# GD32F527 register map
File version: 1.0
CPU: CM33 r0p1, little endian, MPU, FPU, 4 interrupt priority bits
Registers are 32-bit, read-write, reset 0x0 unless marked. A register's access mark holds for its fields unless they carry their own. Offsets are from the block's base; [hi:lo] are bit positions; lines under a group give offsets from that group; {n}, {i} and the like mark numbered series.

## ADC0 — Analog to digital converter
Base 0x40012000
Same registers: ADC1 0x40012100, ADC2 0x40012200
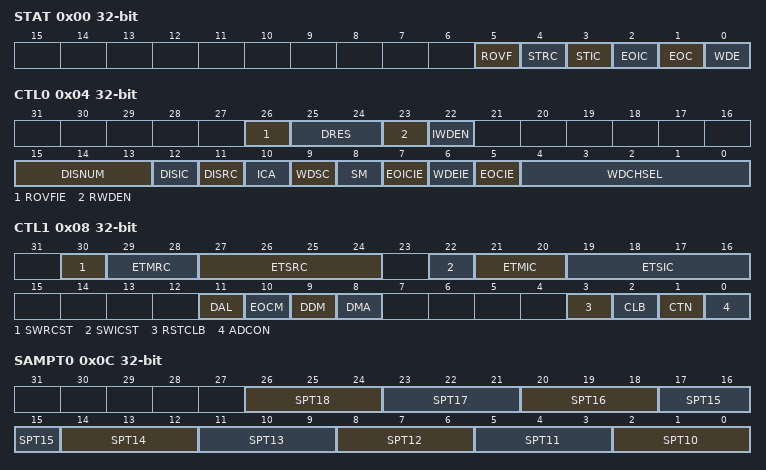
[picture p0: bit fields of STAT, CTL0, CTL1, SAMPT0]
0x00 STAT — status register
  [5] ROVF — Regular data register overflow
  [4] STRC — Start flag of regular channel group
  [3] STIC — Start flag of inserted channel group
  [2] EOIC — End of inserted group conversion flag
  [1] EOC — End of group conversion flag
  [0] WDE — Analog watchdog event flag
0x04 CTL0 — control register 0
  [26] ROVFIE — Interrupt enable for ROVF
  [25:24] DRES — ADC data resolution
  [23] RWDEN — Regular channel analog watchdog enable
  [22] IWDEN — Inserted channel analog watchdog enable
  [15:13] DISNUM — Number of conversions in discontinuous mode
  [12] DISIC — Discontinuous mode on inserted channels
  [11] DISRC — Discontinuous mode on regular channels
  [10] ICA — Inserted channel group convert automatically
  [9] WDSC — When in scan mode, analog watchdog is effective on a single channel
  [8] SM — Scan mode
  [7] EOICIE — Interrupt enable for EOIC
  [6] WDEIE — Analog watchdog WDE
  [5] EOCIE — Interrupt enable for EOC
  [4:0] WDCHSEL — Analog watchdog channel select
0x08 CTL1 — control register 1
  [30] SWRCST — Software start on regular channel
  [29:28] ETMRC — External trigger mode for regular channel
  [27:24] ETSRC — External trigger select for regular channel
  [22] SWICST — Software start on inserted channel
  [21:20] ETMIC — External trigger mode for inserted channel
  [19:16] ETSIC — External trigger select for inserted channel
  [11] DAL — Data alignment
  [10] EOCM — End of conversion mode
  [9] DDM — DMA disable mode
  [8] DMA — DMA request enable
  [3] RSTCLB — Reset calibration
  [2] CLB — ADC calibration
  [1] CTN — Continuous mode
  [0] ADCON
0x0C SAMPT0 — Sample time register 0
  [3n-28:3n-30] SPT{n} (n=10..18) — Channel {n} sample time selection
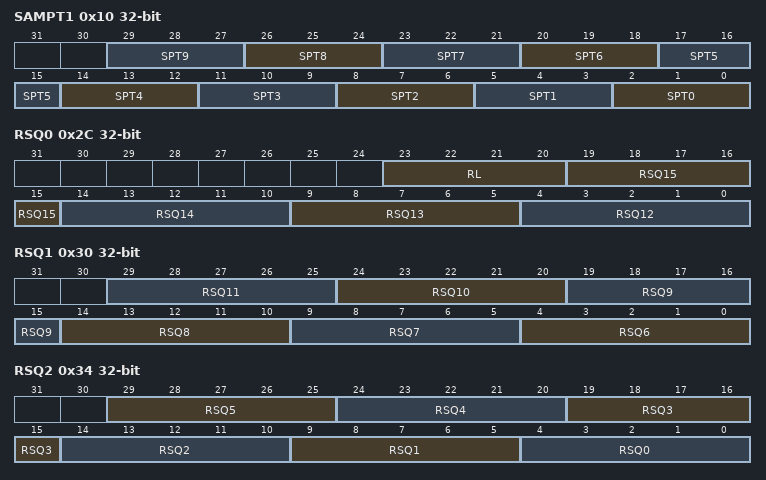
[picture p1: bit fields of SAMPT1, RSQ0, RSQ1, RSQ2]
0x10 SAMPT1 — Sample time register 1
  [3n+2:3n] SPT{n} (n=0..9) — Channel {n} sample time selection
{0x14+4i} IOFF{i} (i=0..3) — Inserted channel data offset register {i}
  [11:0] IOFF — Data offset for inserted channel {i}
0x24 WDHT reset 0xFFF — watchdog higher threshold register
  [11:0] WDHT — Analog watchdog higher threshold
0x28 WDLT — watchdog lower threshold register
  [11:0] WDLT — Analog watchdog lower threshold
0x2C RSQ0 — regular sequence register 0
  [23:20] RL — Regular channel group length
  [5n-56:5n-60] RSQ{n} (n=12..15) — {n+1}th conversion in regular sequence
0x30 RSQ1 — regular sequence register 1
  [5n-26:5n-30] RSQ{n} (n=6..11) — {n+1}th conversion in regular sequence
0x34 RSQ2 — regular sequence register 2
  [29:25] RSQ5 — 6th conversion in regular sequence
  [24:20] RSQ4 — 5th conversion in regular sequence
  [19:15] RSQ3 — 4th conversion in regular sequence
  [14:10] RSQ2 — 3rd conversion in regular sequence
  [9:5] RSQ1 — 2nd conversion in regular sequence
  [4:0] RSQ0 — 1st conversion in regular sequence
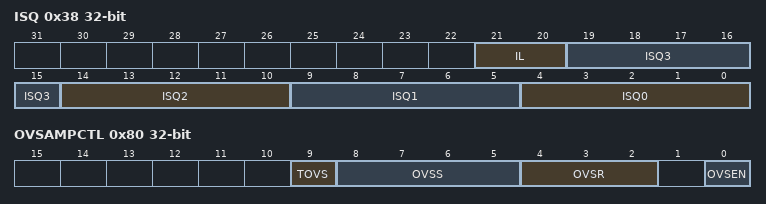
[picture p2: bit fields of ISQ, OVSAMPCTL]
0x38 ISQ — Inserted sequence register
  [21:20] IL — Inserted channel group length
  [19:15] ISQ3 — 4th conversion in inserted sequence
  [14:10] ISQ2 — 3rd conversion in inserted sequence
  [9:5] ISQ1 — 2nd conversion in inserted sequence
  [4:0] ISQ0 — 1st conversion in inserted sequence
{0x3C+4i} IDATA{i} ro (i=0..3) — Inserted data register {i}
  [15:0] IDATAn — Inserted number n conversion data
0x4C RDATA ro — regular data register
  [15:0] RDATA — Regular channel data
0x80 OVSAMPCTL ro — Oversample control register
  [9] TOVS — Triggered Oversampling
  [8:5] OVSS — Oversampling shift
  [4:2] OVSR — Oversampling ratio
  [0] OVSEN — Oversampling Enable

## ADC_Common — common ADC register
Base 0x40012300
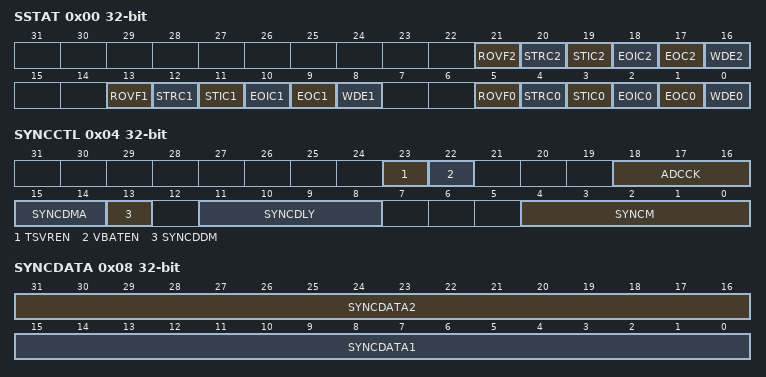
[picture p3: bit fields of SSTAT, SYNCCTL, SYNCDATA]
0x00 SSTAT ro — summary status register
  [21] ROVF2 — This bit equals to the ROVF bit of ADC2
  [20] STRC2 — This bit equals to the STRC bit of ADC2
  [19] STIC2 — This bit equals to the STIC bit of ADC2
  [18] EOIC2 — This bit equals to the EOIC bit of ADC2
  [17] EOC2 — This bit equals to the EOC bit of ADC2
  [16] WDE2 — This bit equals to the WDE bit of ADC2
  [13] ROVF1 — This bit equals to the ROVF bit of ADC1
  [12] STRC1 — This bit equals to the STRC bit of ADC1
  [11] STIC1 — This bit equals to the STIC bit of ADC1
  [10] EOIC1 — This bit equals to the EOIC bit of ADC1
  [9] EOC1 — This bit equals to the EOC bit of ADC1
  [8] WDE1 — This bit equals to the WDE bit of ADC1
  [5] ROVF0 — This bit equals to the ROVF bit of ADC0
  [4] STRC0 — This bit equals to the STRC bit of ADC0
  [3] STIC0 — This bit equals to the STIC bit of ADC0
  [2] EOIC0 — This bit equals to the EOIC bit of ADC0
  [1] EOC0 — This bit equals to the EOC bit of ADC0
  [0] WDE0 — This bit equals to the WDE bit of ADC0
0x04 SYNCCTL — sync control register
  [23] TSVREN — Channel 16 (temperature sensor) and 17 (internal reference voltage) enable of ADC0.
  [22] VBATEN — Channel 18 (1/4 voltage of external battery) enable of ADC0.
  [18:16] ADCCK — ADC clock.
  [15:14] SYNCDMA — ADC sync DMA mode selection
  [13] SYNCDDM — ADC sync DMA disable mode
  [11:8] SYNCDLY — ADC sync delay
  [4:0] SYNCM — ADC sync mode
0x08 SYNCDATA ro — Sync regular data register
  [31:16] SYNCDATA2 — Regular data2 in ADC sync mode
  [15:0] SYNCDATA1 — Regular data1 in ADC sync mode
